VERSION ""

NS_ :

BS_:

BU_: Inverter VCU

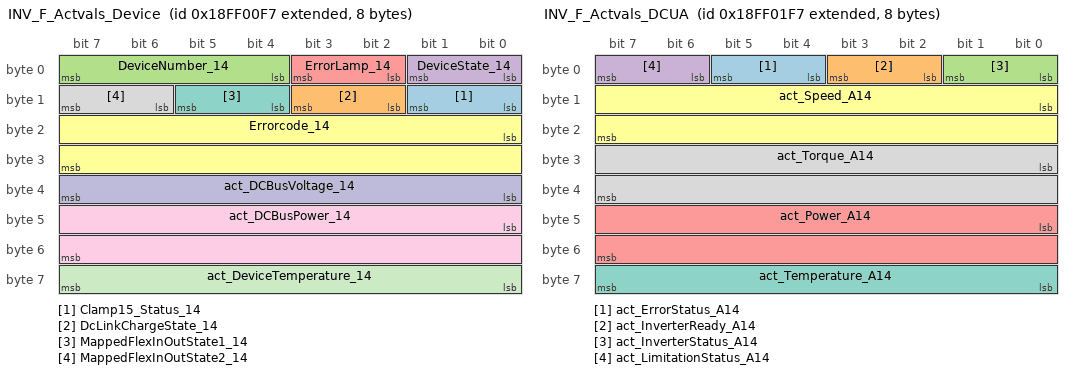
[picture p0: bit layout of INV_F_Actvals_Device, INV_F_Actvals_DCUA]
BO_ 2566848759 INV_F_Actvals_Device: 8 Inverter
 SG_ Clamp15_Status_14  : 8|2@1+ (1,0) [0|3] ""  VCU
 SG_ DcLinkChargeState_14  : 10|2@1+ (1,0) [0|3] ""  VCU
 SG_ DeviceNumber_14  : 4|4@1+ (1,0) [0|15] ""  VCU
 SG_ DeviceState_14  : 0|2@1+ (1,0) [0|3] ""  VCU
 SG_ ErrorLamp_14  : 2|2@1+ (1,0) [0|3] ""  VCU
 SG_ Errorcode_14  : 16|16@1+ (1,0) [0|65535] ""  VCU
 SG_ MappedFlexInOutState1_14  : 12|2@1+ (1,0) [0|3] ""  VCU
 SG_ MappedFlexInOutState2_14  : 14|2@1+ (1,0) [0|3] ""  VCU
 SG_ act_DCBusPower_14  : 40|16@1+ (0.005,-160) [-160|167.675] "kW"  VCU
 SG_ act_DCBusVoltage_14  : 32|8@1+ (4,0) [0|1020] "V"  VCU
 SG_ act_DeviceTemperature_14  : 56|8@1+ (1,-40) [-40|215] "°C"  VCU

BO_ 2566849015 INV_F_Actvals_DCUA: 8 Inverter
 SG_ act_ErrorStatus_A14  : 4|2@1+ (1,0) [0|3] ""  VCU
 SG_ act_InverterReady_A14  : 2|2@1+ (1,0) [0|3] ""  VCU
 SG_ act_InverterStatus_A14  : 0|2@1+ (1,0) [0|3] ""  VCU
 SG_ act_LimitationStatus_A14  : 6|2@1+ (1,0) [0|3] ""  VCU
 SG_ act_Power_A14  : 40|16@1+ (0.005,-160) [-160|167.675] "kW"  VCU
 SG_ act_Speed_A14  : 8|16@1+ (1,-32000) [-32000|33535] "rpm"  VCU
 SG_ act_Temperature_A14  : 56|8@1+ (1,-40) [-40|215] "°C"  VCU
 SG_ act_Torque_A14  : 24|16@1+ (0.2,-6400) [-6400|6707.000000000001] "Nm"  VCU

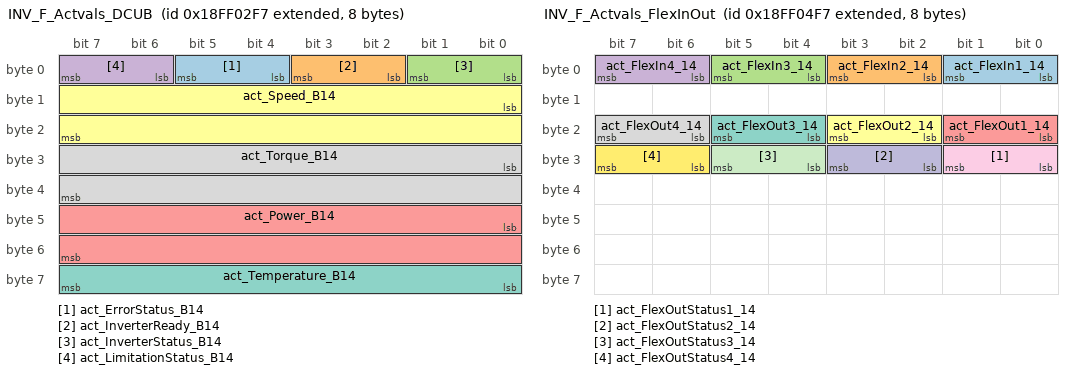
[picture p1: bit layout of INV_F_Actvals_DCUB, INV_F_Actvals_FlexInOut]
BO_ 2566849271 INV_F_Actvals_DCUB: 8 Inverter
 SG_ act_ErrorStatus_B14  : 4|2@1+ (1,0) [0|3] ""  VCU
 SG_ act_InverterReady_B14  : 2|2@1+ (1,0) [0|3] ""  VCU
 SG_ act_InverterStatus_B14  : 0|2@1+ (1,0) [0|3] ""  VCU
 SG_ act_LimitationStatus_B14  : 6|2@1+ (1,0) [0|3] ""  VCU
 SG_ act_Power_B14  : 40|16@1+ (0.005,-160) [-160|167.675] "kW"  VCU
 SG_ act_Speed_B14  : 8|16@1+ (1,-32000) [-32000|33535] "rpm"  VCU
 SG_ act_Temperature_B14  : 56|8@1+ (1,-40) [-40|215] "°C"  VCU
 SG_ act_Torque_B14  : 24|16@1+ (0.2,-6400) [-6400|6707.000000000001] "Nm"  VCU

BO_ 2566849783 INV_F_Actvals_FlexInOut: 8 Inverter
 SG_ act_FlexIn1_14  : 0|2@1+ (1,0) [0|3] ""  VCU
 SG_ act_FlexIn2_14  : 2|2@1+ (1,0) [0|3] ""  VCU
 SG_ act_FlexIn3_14  : 4|2@1+ (1,0) [0|3] ""  VCU
 SG_ act_FlexIn4_14  : 6|2@1+ (1,0) [0|3] ""  VCU
 SG_ act_FlexOut1_14  : 16|2@1+ (1,0) [0|3] ""  VCU
 SG_ act_FlexOut2_14  : 18|2@1+ (1,0) [0|3] ""  VCU
 SG_ act_FlexOut3_14  : 20|2@1+ (1,0) [0|3] ""  VCU
 SG_ act_FlexOut4_14  : 22|2@1+ (1,0) [0|3] ""  VCU
 SG_ act_FlexOutStatus1_14  : 24|2@1+ (1,0) [0|3] ""  VCU
 SG_ act_FlexOutStatus2_14  : 26|2@1+ (1,0) [0|3] ""  VCU
 SG_ act_FlexOutStatus3_14  : 28|2@1+ (1,0) [0|3] ""  VCU
 SG_ act_FlexOutStatus4_14  : 30|2@1+ (1,0) [0|3] ""  VCU

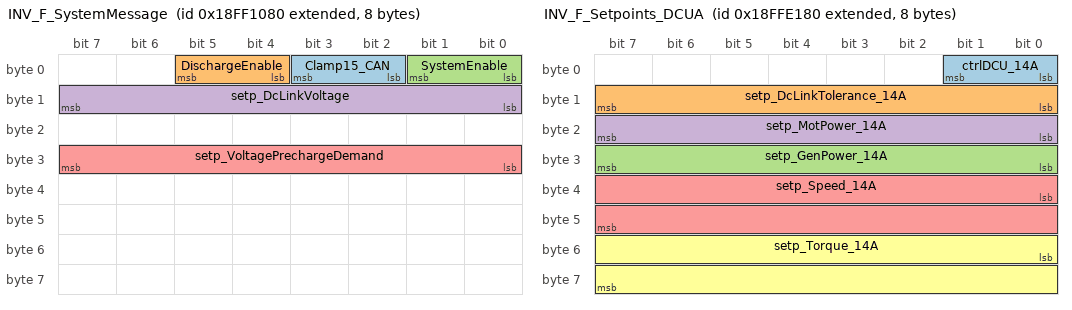
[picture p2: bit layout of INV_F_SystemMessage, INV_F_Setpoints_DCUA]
BO_ 2566852736 INV_F_SystemMessage: 8 VCU
 SG_ Clamp15_CAN  : 2|2@1+ (1,0) [0|3] ""  Inverter
 SG_ DischargeEnable  : 4|2@1+ (1,0) [0|3] ""  Inverter
 SG_ SystemEnable  : 0|2@1+ (1,0) [0|3] ""  Inverter
 SG_ setp_DcLinkVoltage  : 8|8@1+ (4,0) [0|1020] "V"  Inverter
 SG_ setp_VoltagePrechargeDemand  : 24|8@1+ (4,0) [0|1020] "V"  Inverter

BO_ 2566906240 INV_F_Setpoints_DCUA: 8 VCU
 SG_ ctrlDCU_14A  : 0|2@1+ (1,0) [0|3] ""  Inverter
 SG_ setp_DcLinkTolerance_14A  : 8|8@1+ (4,0) [0|1020] "V"  Inverter
 SG_ setp_GenPower_14A  : 24|8@1+ (1,0) [0|250] "%"  Inverter
 SG_ setp_MotPower_14A  : 16|8@1+ (1,0) [0|250] "%"  Inverter
 SG_ setp_Speed_14A  : 32|16@1+ (1,-32000) [-32000|33535] "rpm"  Inverter
 SG_ setp_Torque_14A  : 48|16@1+ (0.2,-6400) [-6400|6707.000000000001] "Nm"  Inverter

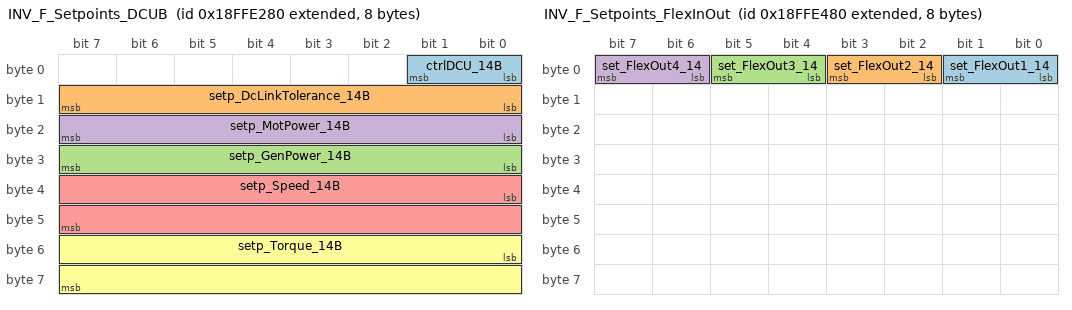
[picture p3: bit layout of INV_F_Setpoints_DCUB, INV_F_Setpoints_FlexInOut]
BO_ 2566906496 INV_F_Setpoints_DCUB: 8 VCU
 SG_ ctrlDCU_14B  : 0|2@1+ (1,0) [0|3] ""  Inverter
 SG_ setp_DcLinkTolerance_14B  : 8|8@1+ (4,0) [0|1020] "V"  Inverter
 SG_ setp_GenPower_14B  : 24|8@1+ (1,0) [0|250] "%"  Inverter
 SG_ setp_MotPower_14B  : 16|8@1+ (1,0) [0|250] "%"  Inverter
 SG_ setp_Speed_14B  : 32|16@1+ (1,-32000) [-32000|33535] "rpm"  Inverter
 SG_ setp_Torque_14B  : 48|16@1+ (0.2,-6400) [-6400|6707.000000000001] "Nm"  Inverter

BO_ 2566907008 INV_F_Setpoints_FlexInOut: 8 VCU
 SG_ set_FlexOut1_14  : 0|2@1+ (1,0) [0|3] ""  Inverter
 SG_ set_FlexOut2_14  : 2|2@1+ (1,0) [0|3] ""  Inverter
 SG_ set_FlexOut3_14  : 4|2@1+ (1,0) [0|3] ""  Inverter
 SG_ set_FlexOut4_14  : 6|2@1+ (1,0) [0|3] ""  Inverter

CM_ BO_ 2566852736 "Broadcast";
BA_DEF_  "DBName" STRING ;
BA_DEF_ BO_  "GenMsgSendType" ENUM  "Cyclic","OnEvent";
BA_DEF_ SG_  "GenSigSendType" ENUM  "NoSigSendType";
BA_DEF_ SG_  "GenSigStartValue" INT 0 0;
BA_DEF_ SG_  "SPN" INT 0 524287;
BA_DEF_DEF_  "DBName" "";
BA_DEF_DEF_  "GenMsgSendType" "NoMsgSendType";
BA_DEF_DEF_  "GenSigSendType" "Cyclic";
BA_DEF_DEF_  "SPN" 0;
BA_ "DBName" "CAN5";
BA_ "GenMsgSendType" BO_ 2566848759 1;
BA_ "GenMsgSendType" BO_ 2566849015 1;
BA_ "GenMsgSendType" BO_ 2566849271 1;
BA_ "GenMsgSendType" BO_ 2566849783 1;
BA_ "GenMsgSendType" BO_ 2566852736 1;
BA_ "GenMsgSendType" BO_ 2566906240 1;
BA_ "GenMsgSendType" BO_ 2566906496 1;
BA_ "GenMsgSendType" BO_ 2566907008 1;
BA_ "GenSigStartValue" SG_ 2566848759 Clamp15_Status_14 0;
BA_ "GenSigStartValue" SG_ 2566848759 DcLinkChargeState_14 0;
BA_ "GenSigStartValue" SG_ 2566848759 DeviceNumber_14 0;
BA_ "GenSigStartValue" SG_ 2566848759 DeviceState_14 0;
BA_ "GenSigStartValue" SG_ 2566848759 ErrorLamp_14 0;
BA_ "GenSigStartValue" SG_ 2566848759 Errorcode_14 0;
BA_ "GenSigStartValue" SG_ 2566848759 MappedFlexInOutState1_14 0;
BA_ "GenSigStartValue" SG_ 2566848759 MappedFlexInOutState2_14 0;
BA_ "GenSigStartValue" SG_ 2566848759 act_DCBusPower_14 32000;
BA_ "GenSigStartValue" SG_ 2566848759 act_DCBusVoltage_14 0;
BA_ "GenSigStartValue" SG_ 2566848759 act_DeviceTemperature_14 40;
BA_ "GenSigStartValue" SG_ 2566849015 act_ErrorStatus_A14 0;
BA_ "GenSigStartValue" SG_ 2566849015 act_InverterReady_A14 0;
BA_ "GenSigStartValue" SG_ 2566849015 act_InverterStatus_A14 0;
BA_ "GenSigStartValue" SG_ 2566849015 act_LimitationStatus_A14 0;
BA_ "GenSigStartValue" SG_ 2566849015 act_Power_A14 32000;
BA_ "GenSigStartValue" SG_ 2566849015 act_Speed_A14 32000;
BA_ "GenSigStartValue" SG_ 2566849015 act_Temperature_A14 40;
BA_ "GenSigStartValue" SG_ 2566849015 act_Torque_A14 32000;
BA_ "GenSigStartValue" SG_ 2566849271 act_ErrorStatus_B14 0;
BA_ "GenSigStartValue" SG_ 2566849271 act_InverterReady_B14 0;
BA_ "GenSigStartValue" SG_ 2566849271 act_InverterStatus_B14 0;
BA_ "GenSigStartValue" SG_ 2566849271 act_LimitationStatus_B14 0;
BA_ "GenSigStartValue" SG_ 2566849271 act_Power_B14 32000;
BA_ "GenSigStartValue" SG_ 2566849271 act_Speed_B14 32000;
BA_ "GenSigStartValue" SG_ 2566849271 act_Temperature_B14 40;
BA_ "GenSigStartValue" SG_ 2566849271 act_Torque_B14 32000;
BA_ "GenSigStartValue" SG_ 2566849783 act_FlexIn1_14 0;
BA_ "GenSigStartValue" SG_ 2566849783 act_FlexIn2_14 0;
BA_ "GenSigStartValue" SG_ 2566849783 act_FlexIn3_14 0;
BA_ "GenSigStartValue" SG_ 2566849783 act_FlexIn4_14 0;
BA_ "GenSigStartValue" SG_ 2566849783 act_FlexOut1_14 0;
BA_ "GenSigStartValue" SG_ 2566849783 act_FlexOut2_14 0;
BA_ "GenSigStartValue" SG_ 2566849783 act_FlexOut3_14 0;
BA_ "GenSigStartValue" SG_ 2566849783 act_FlexOut4_14 0;
BA_ "GenSigStartValue" SG_ 2566849783 act_FlexOutStatus1_14 0;
BA_ "GenSigStartValue" SG_ 2566849783 act_FlexOutStatus2_14 0;
BA_ "GenSigStartValue" SG_ 2566849783 act_FlexOutStatus3_14 0;
BA_ "GenSigStartValue" SG_ 2566849783 act_FlexOutStatus4_14 0;
BA_ "GenSigStartValue" SG_ 2566852736 Clamp15_CAN 0;
BA_ "GenSigStartValue" SG_ 2566852736 DischargeEnable 0;
BA_ "GenSigStartValue" SG_ 2566852736 SystemEnable 0;
BA_ "GenSigStartValue" SG_ 2566852736 setp_DcLinkVoltage 0;
BA_ "GenSigStartValue" SG_ 2566852736 setp_VoltagePrechargeDemand 0;
BA_ "GenSigStartValue" SG_ 2566906240 ctrlDCU_14A 0;
BA_ "GenSigStartValue" SG_ 2566906240 setp_DcLinkTolerance_14A 0;
BA_ "GenSigStartValue" SG_ 2566906240 setp_GenPower_14A 0;
BA_ "GenSigStartValue" SG_ 2566906240 setp_MotPower_14A 0;
BA_ "GenSigStartValue" SG_ 2566906240 setp_Speed_14A 32000;
BA_ "GenSigStartValue" SG_ 2566906240 setp_Torque_14A 32000;
BA_ "GenSigStartValue" SG_ 2566906496 ctrlDCU_14B 0;
BA_ "GenSigStartValue" SG_ 2566906496 setp_DcLinkTolerance_14B 0;
BA_ "GenSigStartValue" SG_ 2566906496 setp_GenPower_14B 0;
BA_ "GenSigStartValue" SG_ 2566906496 setp_MotPower_14B 0;
BA_ "GenSigStartValue" SG_ 2566906496 setp_Speed_14B 32000;
BA_ "GenSigStartValue" SG_ 2566906496 setp_Torque_14B 32000;
BA_ "GenSigStartValue" SG_ 2566907008 set_FlexOut1_14 0;
BA_ "GenSigStartValue" SG_ 2566907008 set_FlexOut2_14 0;
BA_ "GenSigStartValue" SG_ 2566907008 set_FlexOut3_14 0;
BA_ "GenSigStartValue" SG_ 2566907008 set_FlexOut4_14 0;
SIG_VALTYPE_ 2566848759 Clamp15_Status_14 : 0;
SIG_VALTYPE_ 2566848759 DcLinkChargeState_14 : 0;
SIG_VALTYPE_ 2566848759 DeviceNumber_14 : 0;
SIG_VALTYPE_ 2566848759 DeviceState_14 : 0;
SIG_VALTYPE_ 2566848759 ErrorLamp_14 : 0;
SIG_VALTYPE_ 2566848759 Errorcode_14 : 0;
SIG_VALTYPE_ 2566848759 MappedFlexInOutState1_14 : 0;
SIG_VALTYPE_ 2566848759 MappedFlexInOutState2_14 : 0;
SIG_VALTYPE_ 2566848759 act_DCBusPower_14 : 0;
SIG_VALTYPE_ 2566848759 act_DCBusVoltage_14 : 0;
SIG_VALTYPE_ 2566848759 act_DeviceTemperature_14 : 0;
SIG_VALTYPE_ 2566849015 act_ErrorStatus_A14 : 0;
SIG_VALTYPE_ 2566849015 act_InverterReady_A14 : 0;
SIG_VALTYPE_ 2566849015 act_InverterStatus_A14 : 0;
SIG_VALTYPE_ 2566849015 act_LimitationStatus_A14 : 0;
SIG_VALTYPE_ 2566849015 act_Power_A14 : 0;
SIG_VALTYPE_ 2566849015 act_Speed_A14 : 0;
SIG_VALTYPE_ 2566849015 act_Temperature_A14 : 0;
SIG_VALTYPE_ 2566849015 act_Torque_A14 : 0;
SIG_VALTYPE_ 2566849271 act_ErrorStatus_B14 : 0;
SIG_VALTYPE_ 2566849271 act_InverterReady_B14 : 0;
SIG_VALTYPE_ 2566849271 act_InverterStatus_B14 : 0;
SIG_VALTYPE_ 2566849271 act_LimitationStatus_B14 : 0;
SIG_VALTYPE_ 2566849271 act_Power_B14 : 0;
SIG_VALTYPE_ 2566849271 act_Speed_B14 : 0;
SIG_VALTYPE_ 2566849271 act_Temperature_B14 : 0;
SIG_VALTYPE_ 2566849271 act_Torque_B14 : 0;
SIG_VALTYPE_ 2566849783 act_FlexIn1_14 : 0;
SIG_VALTYPE_ 2566849783 act_FlexIn2_14 : 0;
SIG_VALTYPE_ 2566849783 act_FlexIn3_14 : 0;
SIG_VALTYPE_ 2566849783 act_FlexIn4_14 : 0;
SIG_VALTYPE_ 2566849783 act_FlexOut1_14 : 0;
SIG_VALTYPE_ 2566849783 act_FlexOut2_14 : 0;
SIG_VALTYPE_ 2566849783 act_FlexOut3_14 : 0;
SIG_VALTYPE_ 2566849783 act_FlexOut4_14 : 0;
SIG_VALTYPE_ 2566849783 act_FlexOutStatus1_14 : 0;
SIG_VALTYPE_ 2566849783 act_FlexOutStatus2_14 : 0;
SIG_VALTYPE_ 2566849783 act_FlexOutStatus3_14 : 0;
SIG_VALTYPE_ 2566849783 act_FlexOutStatus4_14 : 0;
SIG_VALTYPE_ 2566852736 Clamp15_CAN : 0;
SIG_VALTYPE_ 2566852736 DischargeEnable : 0;
SIG_VALTYPE_ 2566852736 SystemEnable : 0;
SIG_VALTYPE_ 2566852736 setp_DcLinkVoltage : 0;
SIG_VALTYPE_ 2566852736 setp_VoltagePrechargeDemand : 0;
SIG_VALTYPE_ 2566906240 ctrlDCU_14A : 0;
SIG_VALTYPE_ 2566906240 setp_DcLinkTolerance_14A : 0;
SIG_VALTYPE_ 2566906240 setp_GenPower_14A : 0;
SIG_VALTYPE_ 2566906240 setp_MotPower_14A : 0;
SIG_VALTYPE_ 2566906240 setp_Speed_14A : 0;
SIG_VALTYPE_ 2566906240 setp_Torque_14A : 0;
SIG_VALTYPE_ 2566906496 ctrlDCU_14B : 0;
SIG_VALTYPE_ 2566906496 setp_DcLinkTolerance_14B : 0;
SIG_VALTYPE_ 2566906496 setp_GenPower_14B : 0;
SIG_VALTYPE_ 2566906496 setp_MotPower_14B : 0;
SIG_VALTYPE_ 2566906496 setp_Speed_14B : 0;
SIG_VALTYPE_ 2566906496 setp_Torque_14B : 0;
SIG_VALTYPE_ 2566907008 set_FlexOut1_14 : 0;
SIG_VALTYPE_ 2566907008 set_FlexOut2_14 : 0;
SIG_VALTYPE_ 2566907008 set_FlexOut3_14 : 0;
SIG_VALTYPE_ 2566907008 set_FlexOut4_14 : 0;
